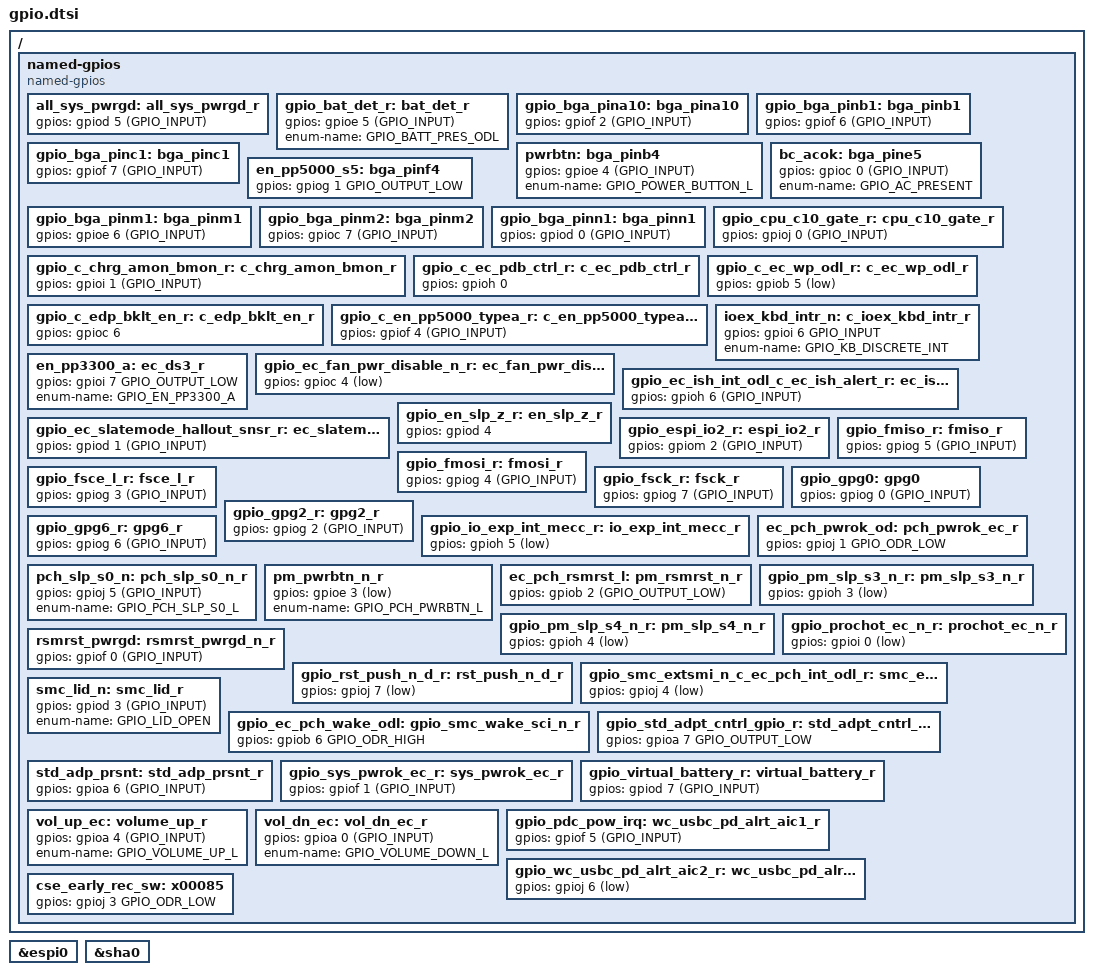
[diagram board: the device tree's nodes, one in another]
/* Copyright 2024 The ChromiumOS Authors
 * Use of this source code is governed by a BSD-style license that can be
 * found in the LICENSE file.
 */

/ {
	named-gpios {
		compatible = "named-gpios";

		all_sys_pwrgd: all_sys_pwrgd_r {
			gpios = <&gpiod 5 (GPIO_INPUT)>;
		};
		gpio_bat_det_r: bat_det_r {
			gpios = <&gpioe 5 (GPIO_INPUT)>;
			enum-name = "GPIO_BATT_PRES_ODL";
		};
		gpio_bga_pina10: bga_pina10 {
			gpios = <&gpiof 2 (GPIO_INPUT)>;
		};
		gpio_bga_pinb1: bga_pinb1 {
			gpios = <&gpiof 6 (GPIO_INPUT)>;
		};
		pwrbtn: bga_pinb4 {
			gpios = <&gpioe 4 (GPIO_INPUT)>;
			enum-name = "GPIO_POWER_BUTTON_L";
		};
		gpio_bga_pinc1: bga_pinc1 {
			gpios = <&gpiof 7 (GPIO_INPUT)>;
		};
		bc_acok: bga_pine5 {
			gpios = <&gpioc 0 (GPIO_INPUT)>;
			enum-name = "GPIO_AC_PRESENT";
		};
		en_pp5000_s5: bga_pinf4 {
			gpios = <&gpiog 1 GPIO_OUTPUT_LOW>;
		};
		gpio_bga_pinm1: bga_pinm1 {
			gpios = <&gpioe 6 (GPIO_INPUT)>;
		};
		gpio_bga_pinm2: bga_pinm2 {
			gpios = <&gpioc 7 (GPIO_INPUT)>;
		};
		gpio_bga_pinn1: bga_pinn1 {
			gpios = <&gpiod 0 (GPIO_INPUT)>;
		};
		gpio_cpu_c10_gate_r: cpu_c10_gate_r {
			gpios = <&gpioj 0 (GPIO_INPUT)>;
		};
		gpio_c_chrg_amon_bmon_r: c_chrg_amon_bmon_r {
			gpios = <&gpioi 1 (GPIO_INPUT)>;
		};
		gpio_c_ec_pdb_ctrl_r: c_ec_pdb_ctrl_r {
			gpios = <&gpioh 0 (GPIO_OUTPUT | GPIO_ACTIVE_HIGH)>;
		};
		gpio_c_ec_wp_odl_r: c_ec_wp_odl_r {
			gpios = <&gpiob 5 (GPIO_INPUT | GPIO_ACTIVE_LOW)>;
		};
		gpio_c_edp_bklt_en_r: c_edp_bklt_en_r {
			gpios = <&gpioc 6 (GPIO_OUTPUT | GPIO_ACTIVE_HIGH)>;
		};
		gpio_c_en_pp5000_typea_r: c_en_pp5000_typea_r {
			gpios = <&gpiof 4 (GPIO_INPUT)>;
		};
		ioex_kbd_intr_n: c_ioex_kbd_intr_r {
			gpios = <&gpioi 6 GPIO_INPUT>;
			enum-name = "GPIO_KB_DISCRETE_INT";
		};
		en_pp3300_a: ec_ds3_r {
			gpios = <&gpioi 7 GPIO_OUTPUT_LOW>;
			enum-name = "GPIO_EN_PP3300_A";
		};
		gpio_ec_fan_pwr_disable_n_r: ec_fan_pwr_disable_n_r {
			gpios = <&gpioc 4 (GPIO_OUTPUT | GPIO_ACTIVE_LOW)>;
		};
		gpio_ec_ish_int_odl_c_ec_ish_alert_r: ec_ish_int_odl_c_ec_ish_alert_r {
			gpios = <&gpioh 6 (GPIO_INPUT)>;
		};
		gpio_ec_slatemode_hallout_snsr_r: ec_slatemode_hallout_snsr_r {
			gpios = <&gpiod 1 (GPIO_INPUT)>;
		};
		gpio_en_slp_z_r: en_slp_z_r {
			gpios = <&gpiod 4 (GPIO_OUTPUT | GPIO_ACTIVE_HIGH)>;
		};
		gpio_espi_io2_r: espi_io2_r {
			gpios = <&gpiom 2 (GPIO_INPUT)>;
		};
		gpio_fmiso_r: fmiso_r {
			gpios = <&gpiog 5 (GPIO_INPUT)>;
		};
		gpio_fmosi_r: fmosi_r {
			gpios = <&gpiog 4 (GPIO_INPUT)>;
		};
		gpio_fsce_l_r: fsce_l_r {
			gpios = <&gpiog 3 (GPIO_INPUT)>;
		};
		gpio_fsck_r: fsck_r {
			gpios = <&gpiog 7 (GPIO_INPUT)>;
		};
		gpio_gpg0: gpg0 {
			gpios = <&gpiog 0 (GPIO_INPUT)>;
		};
		gpio_gpg2_r: gpg2_r {
			gpios = <&gpiog 2 (GPIO_INPUT)>;
		};
		gpio_gpg6_r: gpg6_r {
			gpios = <&gpiog 6 (GPIO_INPUT)>;
		};
		gpio_io_exp_int_mecc_r: io_exp_int_mecc_r {
			gpios = <&gpioh 5 (GPIO_INPUT | GPIO_ACTIVE_LOW)>;
		};
		/*gpio_kso16_r: kso16_r {
			gpios = <&gpioc 3 (GPIO_INPUT)>;
		};*/
		/*gpio_kso17_r: kso17_r {
			gpios = <&gpioc 5 (GPIO_INPUT)>;
		};*/
		ec_pch_pwrok_od: pch_pwrok_ec_r {
			gpios = <&gpioj 1 GPIO_ODR_LOW>;
		};
		pch_slp_s0_n: pch_slp_s0_n_r {
			gpios = <&gpioj 5 (GPIO_INPUT)>;
			enum-name = "GPIO_PCH_SLP_S0_L";
		};
		pm_pwrbtn_n_r {
			gpios = <&gpioe 3 (GPIO_OUTPUT | GPIO_ACTIVE_LOW)>;
			enum-name = "GPIO_PCH_PWRBTN_L";
		};
		ec_pch_rsmrst_l: pm_rsmrst_n_r {
			gpios = <&gpiob 2 (GPIO_OUTPUT_LOW)>;
		};
		gpio_pm_slp_s3_n_r: pm_slp_s3_n_r {
			gpios = <&gpioh 3 (GPIO_INPUT | GPIO_ACTIVE_LOW)>;
		};
		gpio_pm_slp_s4_n_r: pm_slp_s4_n_r {
			gpios = <&gpioh 4 (GPIO_INPUT | GPIO_ACTIVE_LOW)>;
		};
		gpio_prochot_ec_n_r: prochot_ec_n_r {
			gpios = <&gpioi 0 (GPIO_INPUT | GPIO_ACTIVE_LOW)>;
		};
		rsmrst_pwrgd: rsmrst_pwrgd_n_r {
			gpios = <&gpiof 0 (GPIO_INPUT)>;
		};
		gpio_rst_push_n_d_r: rst_push_n_d_r {
			gpios = <&gpioj 7 (GPIO_OUTPUT | GPIO_ACTIVE_LOW)>;
		};
		gpio_smc_extsmi_n_c_ec_pch_int_odl_r: smc_extsmi_n_c_ec_pch_int_odl_r {
			gpios = <&gpioj 4 (GPIO_OUTPUT | GPIO_ACTIVE_LOW)>;
		};
		smc_lid_n: smc_lid_r {
			gpios = <&gpiod 3 (GPIO_INPUT)>;
			enum-name = "GPIO_LID_OPEN";
		};
		gpio_ec_pch_wake_odl: gpio_smc_wake_sci_n_r {
			gpios = <&gpiob 6 GPIO_ODR_HIGH>;
		};
		gpio_std_adpt_cntrl_gpio_r: std_adpt_cntrl_gpio_r {
			gpios = <&gpioa 7 GPIO_OUTPUT_LOW>;
		};
		std_adp_prsnt: std_adp_prsnt_r {
			gpios = <&gpioa 6 (GPIO_INPUT)>;
		};
		gpio_sys_pwrok_ec_r: sys_pwrok_ec_r {
			gpios = <&gpiof 1 (GPIO_INPUT)>;
		};
		gpio_virtual_battery_r: virtual_battery_r {
			gpios = <&gpiod 7 (GPIO_INPUT)>;
		};
		vol_up_ec: volume_up_r {
			gpios = <&gpioa 4 (GPIO_INPUT)>;
			enum-name = "GPIO_VOLUME_UP_L";
		};
		vol_dn_ec: vol_dn_ec_r {
			gpios = <&gpioa 0 (GPIO_INPUT)>;
			enum-name = "GPIO_VOLUME_DOWN_L";
		};
		gpio_pdc_pow_irq: wc_usbc_pd_alrt_aic1_r {
			gpios = <&gpiof 5 (GPIO_INPUT)>;
		};
		gpio_wc_usbc_pd_alrt_aic2_r: wc_usbc_pd_alrt_aic2_r {
			gpios = <&gpioj 6 (GPIO_INPUT | GPIO_ACTIVE_LOW)>;
		};
		cse_early_rec_sw: x00085 {
			gpios = <&gpioj 3 GPIO_ODR_LOW>;
		};
	};
};

/* AP interface */
&espi0 {
	status = "okay";
};

&sha0 {
	status = "okay";
};
